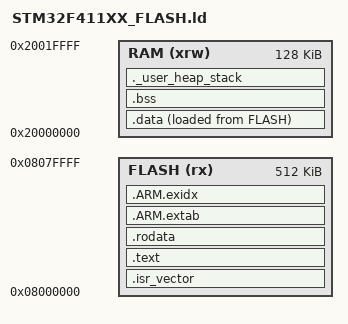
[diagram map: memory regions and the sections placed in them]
/* Entry Point */
ENTRY(Reset_Handler)

/* Memory layout */
MEMORY
{
  FLASH (rx)  : ORIGIN = 0x08000000, LENGTH = 512K
  RAM   (xrw) : ORIGIN = 0x20000000, LENGTH = 128K
}

/* Stack top */
_estack = ORIGIN(RAM) + LENGTH(RAM);

/* Heap and stack size */
_Min_Heap_Size = 0x1000;      /* required amount of heap  */
_Min_Stack_Size = 0x1000; /* required amount of stack */

SECTIONS
{
  /* Interrupt vectors */
  .isr_vector :
  {
    . = ALIGN(4);
    KEEP(*(.isr_vector))
    . = ALIGN(4);
  } >FLASH

  /* Program code */
  .text :
  {
    . = ALIGN(4);
    *(.text)
    *(.text*)
    *(.glue_7)
    *(.glue_7t)
    *(.eh_frame)

    KEEP(*(.init))
    KEEP(*(.fini))

    . = ALIGN(4);
    _etext = .;
  } >FLASH

  /* Read-only data */
  .rodata :
  {
    . = ALIGN(4);
    *(.rodata)
    *(.rodata*)
    . = ALIGN(4);
  } >FLASH

  /* ARM exception tables */
  .ARM.extab :
  {
    *(.ARM.extab* .gnu.linkonce.armextab.*)
  } >FLASH

  .ARM.exidx :
  {
    __exidx_start = .;
    *(.ARM.exidx*)
    __exidx_end = .;
  } >FLASH

  /* Used by startup to initialize data */
  _sidata = LOADADDR(.data);

  /* Initialized data */
  .data :
  {
    . = ALIGN(4);
    _sdata = .;
    *(.data)
    *(.data*)
    *(.RamFunc)
    *(.RamFunc*)
    . = ALIGN(4);
    _edata = .;
  } >RAM AT> FLASH

  /* Uninitialized data */
  .bss (NOLOAD) :
  {
    . = ALIGN(4);
    _sbss = .;
    __bss_start__ = _sbss;
    *(.bss)
    *(.bss*)
    *(COMMON)
    . = ALIGN(4);
    _ebss = .;
    __bss_end__ = _ebss;
  } >RAM

  /* Heap and stack */
  ._user_heap_stack (NOLOAD) :
  {
    . = ALIGN(8);
    PROVIDE(end = .);
    PROVIDE(_end = .);
    . = . + _Min_Heap_Size;
    . = . + _Min_Stack_Size;
    . = ALIGN(8);
  } >RAM

  /* Discard unused libraries */
  /DISCARD/ :
  {
    libc.a:*(*)
    libm.a:*(*)
    libgcc.a:*(*)
  }
}
